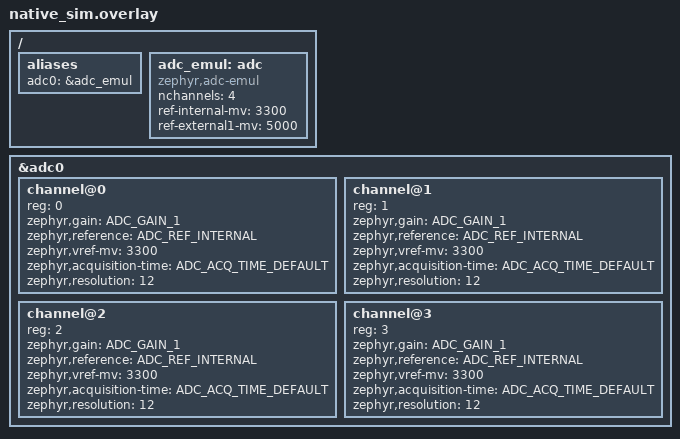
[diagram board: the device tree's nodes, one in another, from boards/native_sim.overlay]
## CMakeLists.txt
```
cmake_minimum_required(VERSION 3.20.0)

set(EXTRA_ZEPHYR_MODULES
    "${CMAKE_CURRENT_SOURCE_DIR}/../../../../modules/eerie_leap_rt_core")

# Use Zephyr's build system
find_package(Zephyr REQUIRED HINTS $ENV{ZEPHYR_BASE})
project(test_guid_generator)

# Enable C++23
set(CMAKE_CXX_STANDARD 23)
set(CMAKE_CXX_STANDARD_REQUIRED ON)
set(CMAKE_CXX_EXTENSIONS OFF)

set(APP_SRC_DIR ${CMAKE_CURRENT_SOURCE_DIR}/../../../../app/src)

include_directories(${APP_SRC_DIR})

set(APP_SRC_SUBSYS_DT_DIR ${APP_SRC_DIR}/subsys/device_tree)
file(GLOB_RECURSE APP_SRC_SUBSYS_DT
  ${APP_SRC_SUBSYS_DIR}/dt_logger.cpp
  ${APP_SRC_SUBSYS_DT_DIR}/dt_adc.cpp
)

set(APP_SRC_ADC_SUBSYS_DIR ${APP_SRC_DIR}/subsys/adc)
file(GLOB_RECURSE APP_SRC_ADC_SUBSYS
  ${APP_SRC_ADC_SUBSYS_DIR}/*.cpp
)

file(GLOB_RECURSE TEST_SOURCES src/*.c src/*.cpp)

# Add all source files to the app target
target_sources(app PRIVATE
  ${APP_SRC_SUBSYS_DT}
  ${APP_SRC_ADC_SUBSYS}
  ${TEST_SOURCES}
)
```

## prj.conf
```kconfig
CONFIG_ZTEST=y

# Language and Compiler
CONFIG_CPP=y
CONFIG_PICOLIBC=y
CONFIG_STD_CPP2B=y
CONFIG_REQUIRES_FULL_LIBCPP=y
CONFIG_CPP_EXCEPTIONS=y
CONFIG_CPP_RTTI=y

# Logging And Debugging
CONFIG_THREAD_ANALYZER=y
CONFIG_THREAD_RUNTIME_STATS=y
CONFIG_THREAD_NAME=y
CONFIG_SYS_HEAP_RUNTIME_STATS=y
CONFIG_TIMING_FUNCTIONS=y

# Memory
CONFIG_HEAP_MEM_POOL_SIZE=100000

# Logging And Debugging
CONFIG_LOG=y

# Random Number Generator
CONFIG_TEST_RANDOM_GENERATOR=y
CONFIG_TIMER_RANDOM_GENERATOR=y

# Hardware
CONFIG_ADC=y

CONFIG_EERIE_LEAP_RT_CORE=y
CONFIG_EERIE_LEAP_CONFIGURATION=y
CONFIG_EERIE_LEAP_ADC=y
```

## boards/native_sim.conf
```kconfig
CONFIG_ADC_EMUL=y
```

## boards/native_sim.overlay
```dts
/ {
	aliases {
		adc0 = &adc_emul;
	};

	adc_emul: adc {
		compatible = "zephyr,adc-emul";
		nchannels = <4>;
		ref-internal-mv = <3300>;
		ref-external1-mv = <5000>;
		#io-channel-cells = <1>;
		status = "okay";
	};
};

&adc0 {
	#address-cells = <1>;
	#size-cells = <0>;

	channel@0 {
		reg = <0>;
		zephyr,gain = "ADC_GAIN_1";
		zephyr,reference = "ADC_REF_INTERNAL";
		zephyr,vref-mv = <3300>;
		zephyr,acquisition-time = <ADC_ACQ_TIME_DEFAULT>;
		zephyr,resolution = <12>;
	};

	channel@1 {
		reg = <1>;
		zephyr,gain = "ADC_GAIN_1";
		zephyr,reference = "ADC_REF_INTERNAL";
		zephyr,vref-mv = <3300>;
		zephyr,acquisition-time = <ADC_ACQ_TIME_DEFAULT>;
		zephyr,resolution = <12>;
	};

	channel@2 {
		reg = <2>;
		zephyr,gain = "ADC_GAIN_1";
		zephyr,reference = "ADC_REF_INTERNAL";
		zephyr,vref-mv = <3300>;
		zephyr,acquisition-time = <ADC_ACQ_TIME_DEFAULT>;
		zephyr,resolution = <12>;
	};

	channel@3 {
		reg = <3>;
		zephyr,gain = "ADC_GAIN_1";
		zephyr,reference = "ADC_REF_INTERNAL";
		zephyr,vref-mv = <3300>;
		zephyr,acquisition-time = <ADC_ACQ_TIME_DEFAULT>;
		zephyr,resolution = <12>;
	};
};
```

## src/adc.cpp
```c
#include <memory>
#include <unordered_set>
#include <zephyr/ztest.h>

#include "utilities/voltage_interpolator/calibration_data.h"
#include "utilities/voltage_interpolator/linear_voltage_interpolator.hpp"

#include "subsys/device_tree/dt_adc.h"
#include "subsys/adc/models/adc_configuration.h"
#include "subsys/adc/adc_simulator.h"
#include "subsys/adc/adc_emulator.h"

using namespace eerie_leap::utilities::voltage_interpolator;
using namespace eerie_leap::subsys::device_tree;
using namespace eerie_leap::subsys::adc;
using namespace eerie_leap::subsys::adc::models;

ZTEST_SUITE(adc, NULL, NULL, NULL, NULL, NULL);

std::shared_ptr<AdcConfiguration> adc_GetTestConfiguration() {
    std::pmr::vector<CalibrationData> adc_calibration_data_samples {
        {0.0, 0.0},
        {3.3, 3.3}
    };

    auto adc_calibration_data_samples_ptr = std::make_shared<std::pmr::vector<CalibrationData>>(adc_calibration_data_samples);
    auto adc_calibrator = std::make_shared<AdcCalibrator>(InterpolationMethod::LINEAR, adc_calibration_data_samples_ptr);

    std::vector<std::shared_ptr<AdcChannelConfiguration>> channel_configurations = {
        std::make_shared<AdcChannelConfiguration>(adc_calibrator),
        std::make_shared<AdcChannelConfiguration>(adc_calibrator),
        std::make_shared<AdcChannelConfiguration>(adc_calibrator),
        std::make_shared<AdcChannelConfiguration>(adc_calibrator)
    };

    auto adc_configuration = std::make_shared<AdcConfiguration>();
    adc_configuration->samples = 40;
    adc_configuration->channel_configurations =
        std::make_shared<std::vector<std::shared_ptr<AdcChannelConfiguration>>>(channel_configurations);

    return adc_configuration;
}

void ReadChannel_has_config(std::shared_ptr<IAdcManager> adc_manager) {
    auto adc_configuration = adc_GetTestConfiguration();

    adc_manager->UpdateConfiguration(adc_configuration);
    adc_manager->Initialize();

    auto channel_reader = adc_manager->GetChannelReader(2);

    std::unordered_set<float> readings;
    for(int j = 0; j < 100; j++) {
        float total = 0;

        for(int i = 0; i < 10; i++) {
            float reading = channel_reader();
            zassert_between_inclusive(reading, 0, 3.3);

            total += reading;
        }

        zassert_equal(readings.count(total), 0);
        readings.insert(total);
    }
}

ZTEST(adc, test_Simulator_ReadChannel_has_config) {
    auto adc = std::make_shared<AdcSimulatorManager>();
    ReadChannel_has_config(adc);
}

ZTEST(adc, test_Emulator_ReadChannel_has_config) {
    DtAdc::Initialize();

    auto adc = std::make_shared<AdcEmulatorManager>(DtAdc::Get().value());
    ReadChannel_has_config(adc);
}

void ReadChannel_no_config(std::shared_ptr<IAdcManager> adc_manager) {
    adc_manager->Initialize();

    try {
        auto channel_reader = adc_manager->GetChannelReader(2);
        channel_reader();
        zassert_true(true, "ReadChannel expected to fail, but it didn't.");
    } catch(...) {
        zassert_true(false, "ReadChannel failed as expected due to missing config.");
    }
}

ZTEST_EXPECT_FAIL(adc, test_Simulator_ReadChannel_no_config);
ZTEST(adc, test_Simulator_ReadChannel_no_config) {
    auto adc = std::make_shared<AdcSimulatorManager>();
    ReadChannel_no_config(adc);
}

ZTEST_EXPECT_FAIL(adc, test_Emulator_ReadChannel_no_config);
ZTEST(adc, test_Emulator_ReadChannel_no_config) {
    DtAdc::Initialize();

    auto adc = std::make_shared<AdcEmulatorManager>(DtAdc::Get().value());
    ReadChannel_no_config(adc);
}

void ReadChannel_out_of_range(std::shared_ptr<IAdcManager> adc_manager) {
    auto adc_configuration = adc_GetTestConfiguration();

    adc_manager->UpdateConfiguration(adc_configuration);
    adc_manager->Initialize();

    try {
        auto channel_reader = adc_manager->GetChannelReader(-2);
        channel_reader();
        zassert_true(true, "ReadChannel expected to fail, but it didn't.");
    } catch(...) {
        zassert_true(false, "ReadChannel failed as expected due to out of range channel.");
    }

    try {
        auto channel_reader = adc_manager->GetChannelReader(4);
        channel_reader();
        zassert_true(true, "ReadChannel expected to fail, but it didn't.");
    } catch(...) {
        zassert_true(false, "ReadChannel failed as expected due to out of range channel.");
    }
}

ZTEST_EXPECT_FAIL(adc, test_Simulator_ReadChannel_out_of_range);
ZTEST(adc, test_Simulator_ReadChannel_out_of_range) {
    auto adc = std::make_shared<AdcSimulatorManager>();
    ReadChannel_out_of_range(adc);
}

ZTEST_EXPECT_FAIL(adc, test_Emulator_ReadChannel_out_of_range);
ZTEST(adc, test_Emulator_ReadChannel_out_of_range) {
    DtAdc::Initialize();

    auto adc = std::make_shared<AdcEmulatorManager>(DtAdc::Get().value());
    ReadChannel_out_of_range(adc);
}
```
